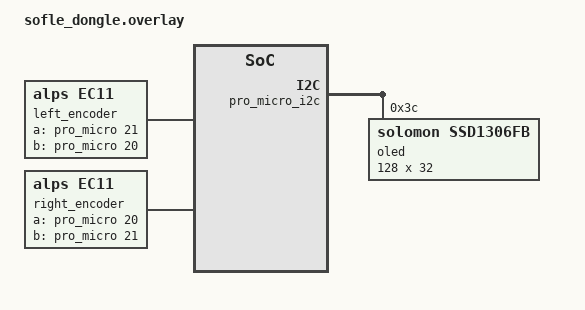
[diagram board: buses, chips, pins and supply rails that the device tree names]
#include <dt-bindings/zmk/matrix_transform.h>

/ {
    chosen {
        zephyr,display = &oled;
    };

    left_encoder: encoder_left {
        compatible = "alps,ec11";
        a-gpios = <&pro_micro 21 (GPIO_ACTIVE_HIGH | GPIO_PULL_UP)>;
        b-gpios = <&pro_micro 20 (GPIO_ACTIVE_HIGH | GPIO_PULL_UP)>;
        steps = <80>;
        status = "okay";
    };

    right_encoder: encoder_right {
        compatible = "alps,ec11";
        a-gpios = <&pro_micro 20 (GPIO_ACTIVE_HIGH | GPIO_PULL_UP)>;
        b-gpios = <&pro_micro 21 (GPIO_ACTIVE_HIGH | GPIO_PULL_UP)>;
        steps = <80>;
        status = "okay";
    };

    sensors: sensors {
        compatible = "zmk,keymap-sensors";
        sensors = <&left_encoder &right_encoder>;
        triggers-per-rotation = <20>;
    };
};

&pro_micro_i2c {
    status = "okay";

    oled: ssd1306@3c {
        compatible = "solomon,ssd1306fb";
        reg = <0x3c>;
        width = <128>;
        height = <32>;
        segment-offset = <0>;
        page-offset = <0>;
        display-offset = <0>;
        multiplex-ratio = <31>;
        segment-remap;
        com-invdir;
        com-sequential;
        inversion-on;
        prechargep = <0x22>;
    };
};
